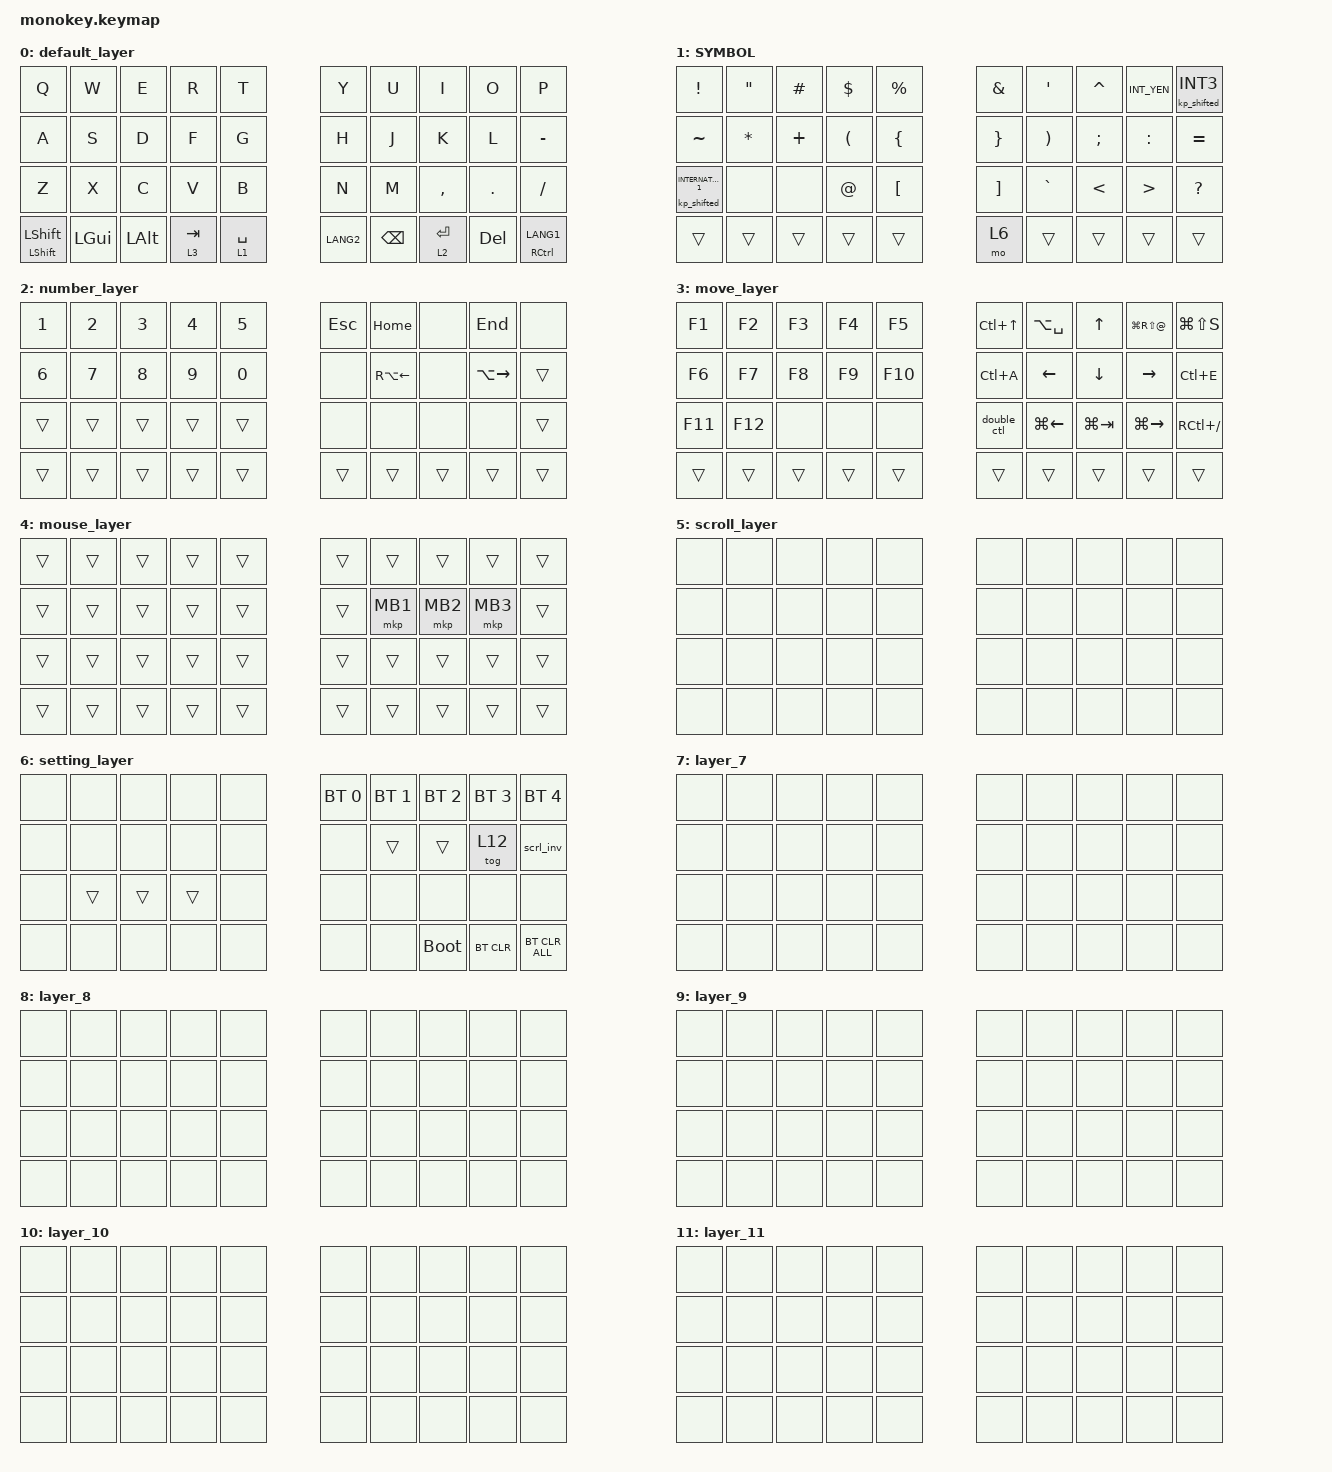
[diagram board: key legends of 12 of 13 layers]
/*
 * Copyright (c) 2024 Conductor Keyboard
 * Generated by Conductor Studio 2.0
 */

#include <dt-bindings/zmk/mouse.h>
#include <behaviors.dtsi>
#include <dt-bindings/zmk/bt.h>
#include <dt-bindings/zmk/keys.h>
#include <dt-bindings/zmk/pointing.h>
#include "override_jis_symbols.h"

#define MOUSE 4
#define SCROLL 1
#define NUM 6

&mt {
    flavor = "tap-preferred";
    tapping-term-ms = <150>;
    quick-tap-ms = <250>;
};

&lt {
    tapping-term-ms = <150>;
    quick-tap-ms = <250>;
    flavor = "tap-preferred";
};

/ {
    combos {
        compatible = "zmk,combos";

        scroll {
            bindings = <&mo SCROLL>;
            key-positions = <17 16>;
            timeout-ms = <50>;
        };

        pair {
            bindings = <&bt BT_SEL 5>;
            key-positions = <0 10 20>;
            timeout-ms = <50>;
        };

        boot {
            bindings = <&bootloader>;
            key-positions = <8 24 4>;
            timeout-ms = <50>;
        };
    };

    behaviors {
        tog_off: tog_off {
            compatible = "zmk,behavior-toggle-layer";
            #binding-cells = <1>;
            display-name = "Toggle Layer Off";
            toggle-mode = "off";
        };

        mt_exit_AML_on_tap: mt_exit_AML_on_tap {
            compatible = "zmk,behavior-hold-tap";
            label = "MT_exit_AML_ON_TAP";
            bindings = <&kp>, <&kp_exit_AML>;

            #binding-cells = <2>;
            tapping-term-ms = <200>;
            flavor = "balanced";
            quick-tap-ms = <200>;
        };
    };

    macros {
        double_ctl: double_ctl {
            compatible = "zmk,behavior-macro";
            #binding-cells = <0>;
            bindings = <&kp LCTRL &kp LCTRL>;
            label = "DOUBLE_CTL";
        };

        exit_AML: exit_AML {
            compatible = "zmk,behavior-macro";
            wait-ms = <0>;
            tap-ms = <0>;
            #binding-cells = <0>;
            bindings = <&tog_off MOUSE>;
            label = "exit_AML";
        };

        kp_exit_AML: kp_exit_AML {
            compatible = "zmk,behavior-macro-one-param";
            wait-ms = <0>;
            tap-ms = <0>;
            #binding-cells = <1>;
            bindings = <&macro_param_1to1 &kp MACRO_PLACEHOLDER &exit_AML>;
            label = "KP_exit_AML";
        };

        // 任意のキーコードを引数で受け取り、Shift + (指定キー) を実行するマクロ
        // LS(INT1)/LS(INT3) などではシフトの判定がうまくいかないためこのマクロで代替

        kp_shifted: kp_shifted {
            compatible = "zmk,behavior-macro-one-param";
            #binding-cells = <1>;
            bindings =
                <&macro_press>,
                <&kp LSHFT>,
                <&macro_tap>,
                <&macro_param_1to1 &kp MACRO_PLACEHOLDER>,
                <&macro_release>,
                <&kp LSHFT>;

            label = "KP_SHIFTED";
        };
    };

    keymap {
        compatible = "zmk,keymap";

        default_layer {
            bindings = <
&kp Q                                      &kp W     &kp E         &kp R      &kp T                     &kp Y          &kp U        &kp I      &kp O       &kp P
&kp A                                      &kp S     &kp D         &kp F      &kp G                     &kp H          &kp J        &kp K      &kp L       &kp MINUS
&kp Z                                      &kp X     &kp C         &kp V      &kp B                     &kp N          &kp M        &kp COMMA  &kp PERIOD  &kp SLASH
&mt_exit_AML_on_tap LEFT_SHIFT LEFT_SHIFT  &kp LGUI  &kp LEFT_ALT  &lt 3 TAB  &lt 1 SPACE  &kp LANG2    &kp BACKSPACE  &lt 2 ENTER             &kp DELETE  &mt_exit_AML_on_tap RCTRL LANG1
            >;

            sensor-bindings = <&inc_dec_kp PG_UP PG_DN>;
        };

        SYMBOL {
            bindings = <
&kp EXCLAMATION              &kp DOUBLE_QUOTES  &kp HASH  &kp DOLLAR            &kp PERCENT                &kp AMPERSAND      &kp SINGLE_QUOTE       &kp CARET      &kp INT_YEN       &kp_shifted INT3
&kp TILDE                    &kp ASTERISK       &kp PLUS  &kp LEFT_PARENTHESIS  &kp LEFT_BRACE             &kp RIGHT_BRACE    &kp RIGHT_PARENTHESIS  &kp SEMICOLON  &kp COLON         &kp EQUAL
&kp_shifted INTERNATIONAL_1  &none              &none     &kp AT_SIGN           &kp LEFT_BRACKET           &kp RIGHT_BRACKET  &kp GRAVE              &kp LESS_THAN  &kp GREATER_THAN  &kp QUESTION
&trans                       &trans             &trans    &trans                &trans            &mo 6    &trans             &trans                                &trans            &trans
            >;
        };

        number_layer {
            bindings = <
&kp NUMBER_1  &kp NUMBER_2  &kp NUMBER_3  &kp NUMBER_4  &kp N5                  &kp ESCAPE  &kp HOME            &none  &kp END              &none
&kp NUMBER_6  &kp NUMBER_7  &kp NUMBER_8  &kp NUMBER_9  &kp NUMBER_0            &none       &kp RA(LEFT_ARROW)  &none  &kp LA(RIGHT_ARROW)  &trans
&trans        &trans        &trans        &trans        &trans                  &none       &none               &none  &none                &trans
&trans        &trans        &trans        &trans        &trans        &trans    &trans      &trans                     &trans               &trans
            >;
        };

        move_layer {
            bindings = <
&kp F1   &kp F2   &kp F3  &kp F4  &kp F5             &kp LC(UP_ARROW)  &kp LA(SPACE)   &kp UP_ARROW    &kp LG(RS(AT))   &kp LG(LS(S))
&kp F6   &kp F7   &kp F8  &kp F9  &kp F10            &kp LC(A)         &kp LEFT_ARROW  &kp DOWN_ARROW  &kp RIGHT_ARROW  &kp LC(E)
&kp F11  &kp F12  &none   &none   &none              &double_ctl       &kp LG(LEFT)    &kp LG(TAB)     &kp LG(RIGHT)    &kp RC(SLASH)
&trans   &trans   &trans  &trans  &trans   &trans    &trans            &trans                          &trans           &trans
            >;
        };

        mouse_layer {
            bindings = <
&trans  &trans  &trans  &trans  &trans            &trans  &trans    &trans    &trans    &trans
&trans  &trans  &trans  &trans  &trans            &trans  &mkp MB1  &mkp MB2  &mkp MB3  &trans
&trans  &trans  &trans  &trans  &trans            &trans  &trans    &trans    &trans    &trans
&trans  &trans  &trans  &trans  &trans  &trans    &trans  &trans              &trans    &trans
            >;
        };

        scroll_layer {
            bindings = <
&none  &none  &none  &none  &none           &none  &none  &none  &none  &none
&none  &none  &none  &none  &none           &none  &none  &none  &none  &none
&none  &none  &none  &none  &none           &none  &none  &none  &none  &none
&none  &none  &none  &none  &none  &none    &none  &none         &none  &none
            >;
        };

        setting_layer {
            bindings = <
&none  &none   &none   &none   &none           &bt BT_SEL 0  &bt BT_SEL 1  &bt BT_SEL 2  &bt BT_SEL 3  &bt BT_SEL 4
&none  &none   &none   &none   &none           &none         &trans        &trans        &tog 12       &scrl_inv
&none  &trans  &trans  &trans  &none           &none         &none         &none         &none         &none
&none  &none   &none   &none   &none  &none    &none         &bootloader                 &bt BT_CLR    &bt BT_CLR_ALL
            >;
        };

        layer_7 {
            bindings = <
&none  &none  &none  &none  &none           &none  &none  &none  &none  &none
&none  &none  &none  &none  &none           &none  &none  &none  &none  &none
&none  &none  &none  &none  &none           &none  &none  &none  &none  &none
&none  &none  &none  &none  &none  &none    &none  &none         &none  &none
            >;
        };

        layer_8 {
            bindings = <
&none  &none  &none  &none  &none           &none  &none  &none  &none  &none
&none  &none  &none  &none  &none           &none  &none  &none  &none  &none
&none  &none  &none  &none  &none           &none  &none  &none  &none  &none
&none  &none  &none  &none  &none  &none    &none  &none         &none  &none
            >;
        };

        layer_9 {
            bindings = <
&none  &none  &none  &none  &none           &none  &none  &none  &none  &none
&none  &none  &none  &none  &none           &none  &none  &none  &none  &none
&none  &none  &none  &none  &none           &none  &none  &none  &none  &none
&none  &none  &none  &none  &none  &none    &none  &none         &none  &none
            >;
        };

        layer_10 {
            bindings = <
&none  &none  &none  &none  &none           &none  &none  &none  &none  &none
&none  &none  &none  &none  &none           &none  &none  &none  &none  &none
&none  &none  &none  &none  &none           &none  &none  &none  &none  &none
&none  &none  &none  &none  &none  &none    &none  &none         &none  &none
            >;
        };

        layer_11 {
            bindings = <
&none  &none  &none  &none  &none           &none  &none  &none  &none  &none
&none  &none  &none  &none  &none           &none  &none  &none  &none  &none
&none  &none  &none  &none  &none           &none  &none  &none  &none  &none
&none  &none  &none  &none  &none  &none    &none  &none         &none  &none
            >;
        };

        /* PRECISION layer (id=12): when active, trackball movement is scaled
         * down for fine cursor control (drafting, detailed work). Toggle with
         * &tog 12. Default bindings mirror mouse_layer so MB1-3 are reachable
         * during precision use; other keys are intentionally NONE to prevent
         * accidental typing while focused on cursor work. */

        precision_layer {
            bindings = <
&none  &none  &none  &none  &none           &none  &none  &none     &none     &none
&none  &none  &none  &none  &none           &none  &none  &mkp MB1  &mkp MB2  &mkp MB3
&none  &none  &none  &none  &none           &none  &none  &none     &none     &none
&none  &none  &none  &none  &none  &none    &none  &none            &none     &tog 12
            >;
        };
    };
};
